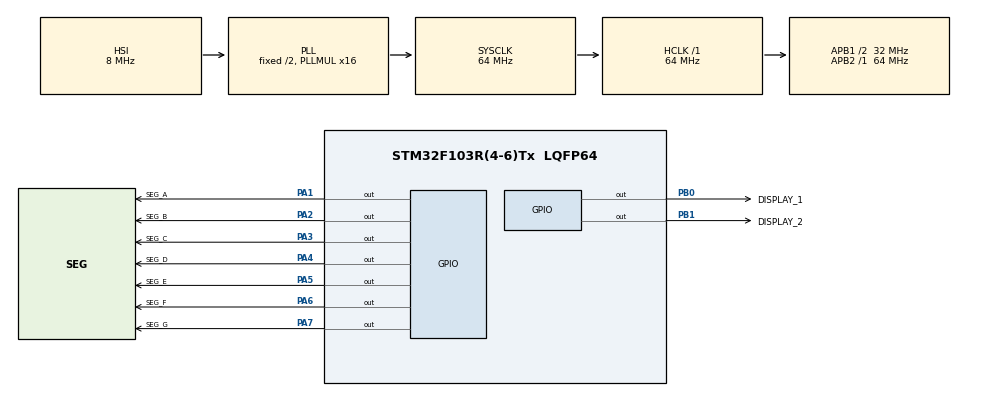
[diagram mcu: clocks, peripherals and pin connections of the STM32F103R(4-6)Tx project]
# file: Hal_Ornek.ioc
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Mcu.Family=STM32F1
PA6.GPIO_Label=SEG_F
PB0.GPIO_Label=DISPLAY_1
RCC.APB1CLKDivider=RCC_HCLK_DIV2
RCC.TimSys_Div=SYSTICK_CLKSOURCE_HCLK_DIV8
VP_SYS_VS_ND.Mode=No_Debug
RCC.SYSCLKSource=RCC_SYSCLKSOURCE_PLLCLK
ProjectManager.StackSize=0x400
ProjectManager.TargetToolchain=STM32CubeIDE
RCC.HCLKFreq_Value=64000000
RCC.APB2TimFreq_Value=64000000
RCC.USBFreq_Value=64000000
PA1.Signal=GPIO_Output
RCC.AHBFreq_Value=64000000
PA5.Signal=GPIO_Output
board=custom
RCC.PLLMUL=RCC_PLL_MUL16
RCC.APB2Freq_Value=64000000
PB1.GPIO_Label=DISPLAY_2
PA1.GPIO_Label=SEG_A
Mcu.Name=STM32F103R(4-6)Tx
PA2.Signal=GPIO_Output
PA4.Signal=GPIO_Output
RCC.SYSCLKFreq_VALUE=64000000
Mcu.Package=LQFP64
PB1.Signal=GPIO_Output
PA6.Signal=GPIO_Output
PA7.GPIO_Label=SEG_G
PA5.GPIO_Label=SEG_E
PA2.GPIO_Label=SEG_B
ProjectManager.HeapSize=0x200
NVIC.PriorityGroup=NVIC_PRIORITYGROUP_4
RCC.APB1TimFreq_Value=64000000
RCC.APB1Freq_Value=32000000
PB0.Signal=GPIO_Output
PA4.GPIO_Label=SEG_D
PA3.GPIO_Label=SEG_C
PA3.Signal=GPIO_Output
PA7.Signal=GPIO_Output

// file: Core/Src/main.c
/* USER CODE BEGIN Header */
/**
 ******************************************************************************
 * @file           : main.c
 * @brief          : Main program body
 ******************************************************************************
 * @attention
 *
 * <h2><center>&copy; Copyright (c) 2021 STMicroelectronics.
 * All rights reserved.</center></h2>
 *
 * This software component is licensed by ST under BSD 3-Clause license,
 * the "License"; You may not use this file except in compliance with the
 * License. You may obtain a copy of the License at:
 *                        opensource.org/licenses/BSD-3-Clause
 *
 ******************************************************************************
 */
/* USER CODE END Header */
#include "main.h"

/* USER CODE BEGIN Includes */
#include "seven_seg.h"
/* USER CODE END Includes */

void SystemClock_Config(void);
static void MX_GPIO_Init(void);

int main(void)
{

  /* MCU Configuration--------------------------------------------------------*/

  /* Reset of all peripherals, Initializes the Flash interface and the Systick. */
  HAL_Init();

  /* Configure the system clock */
  SystemClock_Config();

  /* Initialize all configured peripherals */
  MX_GPIO_Init();

  /* Infinite loop */
    while (1)
    {

    /* USER CODE BEGIN 3 */

        sevenSeg_loop();

    }
  /* USER CODE END 3 */
}

void SystemClock_Config(void)
{
  RCC_OscInitTypeDef RCC_OscInitStruct = {0};
  RCC_ClkInitTypeDef RCC_ClkInitStruct = {0};

  /** Initializes the RCC Oscillators according to the specified parameters
  * in the RCC_OscInitTypeDef structure.
  */
  RCC_OscInitStruct.OscillatorType = RCC_OSCILLATORTYPE_HSI;
  RCC_OscInitStruct.HSIState = RCC_HSI_ON;
  RCC_OscInitStruct.HSICalibrationValue = RCC_HSICALIBRATION_DEFAULT;
  RCC_OscInitStruct.PLL.PLLState = RCC_PLL_ON;
  RCC_OscInitStruct.PLL.PLLSource = RCC_PLLSOURCE_HSI_DIV2;
  RCC_OscInitStruct.PLL.PLLMUL = RCC_PLL_MUL16;
  if (HAL_RCC_OscConfig(&RCC_OscInitStruct) != HAL_OK)
  {
    Error_Handler();
  }
  /** Initializes the CPU, AHB and APB buses clocks
  */
  RCC_ClkInitStruct.ClockType = RCC_CLOCKTYPE_HCLK|RCC_CLOCKTYPE_SYSCLK
                              |RCC_CLOCKTYPE_PCLK1|RCC_CLOCKTYPE_PCLK2;
  RCC_ClkInitStruct.SYSCLKSource = RCC_SYSCLKSOURCE_PLLCLK;
  RCC_ClkInitStruct.AHBCLKDivider = RCC_SYSCLK_DIV1;
  RCC_ClkInitStruct.APB1CLKDivider = RCC_HCLK_DIV2;
  RCC_ClkInitStruct.APB2CLKDivider = RCC_HCLK_DIV1;

  if (HAL_RCC_ClockConfig(&RCC_ClkInitStruct, FLASH_LATENCY_2) != HAL_OK)
  {
    Error_Handler();
  }
}

static void MX_GPIO_Init(void)
{
  GPIO_InitTypeDef GPIO_InitStruct = {0};

  /* GPIO Ports Clock Enable */
  __HAL_RCC_GPIOA_CLK_ENABLE();
  __HAL_RCC_GPIOB_CLK_ENABLE();

  /*Configure GPIO pin Output Level */
  HAL_GPIO_WritePin(GPIOA, SEG_A_Pin|SEG_B_Pin|SEG_C_Pin|SEG_D_Pin
                          |SEG_E_Pin|SEG_F_Pin|SEG_G_Pin, GPIO_PIN_RESET);

  /*Configure GPIO pin Output Level */
  HAL_GPIO_WritePin(GPIOB, DISPLAY_1_Pin|DISPLAY_2_Pin, GPIO_PIN_RESET);

  /*Configure GPIO pins : SEG_A_Pin SEG_B_Pin SEG_C_Pin SEG_D_Pin
                           SEG_E_Pin SEG_F_Pin SEG_G_Pin */
  GPIO_InitStruct.Pin = SEG_A_Pin|SEG_B_Pin|SEG_C_Pin|SEG_D_Pin
                          |SEG_E_Pin|SEG_F_Pin|SEG_G_Pin;
  GPIO_InitStruct.Mode = GPIO_MODE_OUTPUT_PP;
  GPIO_InitStruct.Pull = GPIO_NOPULL;
  GPIO_InitStruct.Speed = GPIO_SPEED_FREQ_LOW;
  HAL_GPIO_Init(GPIOA, &GPIO_InitStruct);

  /*Configure GPIO pins : DISPLAY_1_Pin DISPLAY_2_Pin */
  GPIO_InitStruct.Pin = DISPLAY_1_Pin|DISPLAY_2_Pin;
  GPIO_InitStruct.Mode = GPIO_MODE_OUTPUT_PP;
  GPIO_InitStruct.Pull = GPIO_NOPULL;
  GPIO_InitStruct.Speed = GPIO_SPEED_FREQ_LOW;
  HAL_GPIO_Init(GPIOB, &GPIO_InitStruct);

}

void Error_Handler(void)
{
    __disable_irq();
    while (1)
    {
    }
}

/************************ (C) COPYRIGHT STMicroelectronics *****END OF FILE****/
